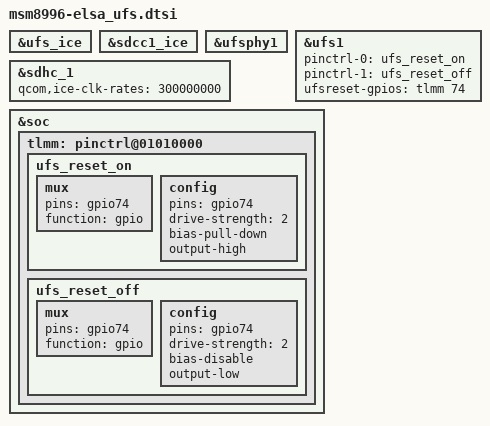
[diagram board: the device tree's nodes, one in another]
/* Copyright (c) 2015, The Linux Foundation. All rights reserved.
 *
 * This program is free software; you can redistribute it and/or modify
 * it under the terms of the GNU General Public License version 2 and
 * only version 2 as published by the Free Software Foundation.
 *
 * This program is distributed in the hope that it will be useful,
 * but WITHOUT ANY WARRANTY; without even the implied warranty of
 * MERCHANTABILITY or FITNESS FOR A PARTICULAR PURPOSE.  See the
 * GNU General Public License for more details.
 */

/* Current storage type is UFS */

&ufs_ice {
	status = "ok";
};

&sdcc1_ice {
        status = "ok";
};

&ufsphy1 {
	status = "ok";
};

&ufs1 {
	status = "ok";
};

&sdhc_1 {
	qcom,ice-clk-rates = <300000000>;
};

&soc {
	tlmm: pinctrl@01010000 {

		ufs_reset_on: ufs_reset_on {
			mux {
				pins = "gpio74";
				function = "gpio";
			};

			config {
				pins = "gpio74";
				drive-strength = <2>;
				bias-pull-down;
				output-high;
		    };
		};

		ufs_reset_off: ufs_reset_off {
			mux {
				pins = "gpio74";
				function = "gpio";
			};

			config {
				pins = "gpio74";
				drive-strength = <2>;
				bias-disable;
				output-low;
			};
		};
	};
};

&ufs1 {
	pinctrl-names = "ufs_res_in_on", "ufs_res_in_off";
	pinctrl-0 = <&ufs_reset_on>;
	pinctrl-1 = <&ufs_reset_off>;
	/* H+ hw - invert signal by FET - UFS_RESET_N is low active */
	ufsreset-gpios = <&tlmm 74 0x0>;
};
